AUTOSAR XML (schema 4-2-2)
package /SUM_APPLICATION
  sender receiver interface SR_R_SUM_INTERFACE
    data VAL1: type=uint32
    data VAL2: type=uint32
  sender receiver interface SR_P_SUM_INTERFACE
    data RESULT: type=uint32
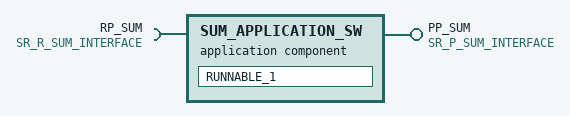
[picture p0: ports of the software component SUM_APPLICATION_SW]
  application sw component type SUM_APPLICATION_SW
    provide port PP_SUM: provided-interface=SR_P_SUM_INTERFACE
    require port RP_SUM: required-interface=SR_R_SUM_INTERFACE
    behavior SUM_RUNNABLES
      runnable RUNNABLE_1
        data-read-access:
          access VAL1: accessed-variable=RP_SUM.VAL1
          access VAL2: accessed-variable=RP_SUM.VAL2
        data-write-access:
          access RESULT: accessed-variable=PP_SUM.RESULT
